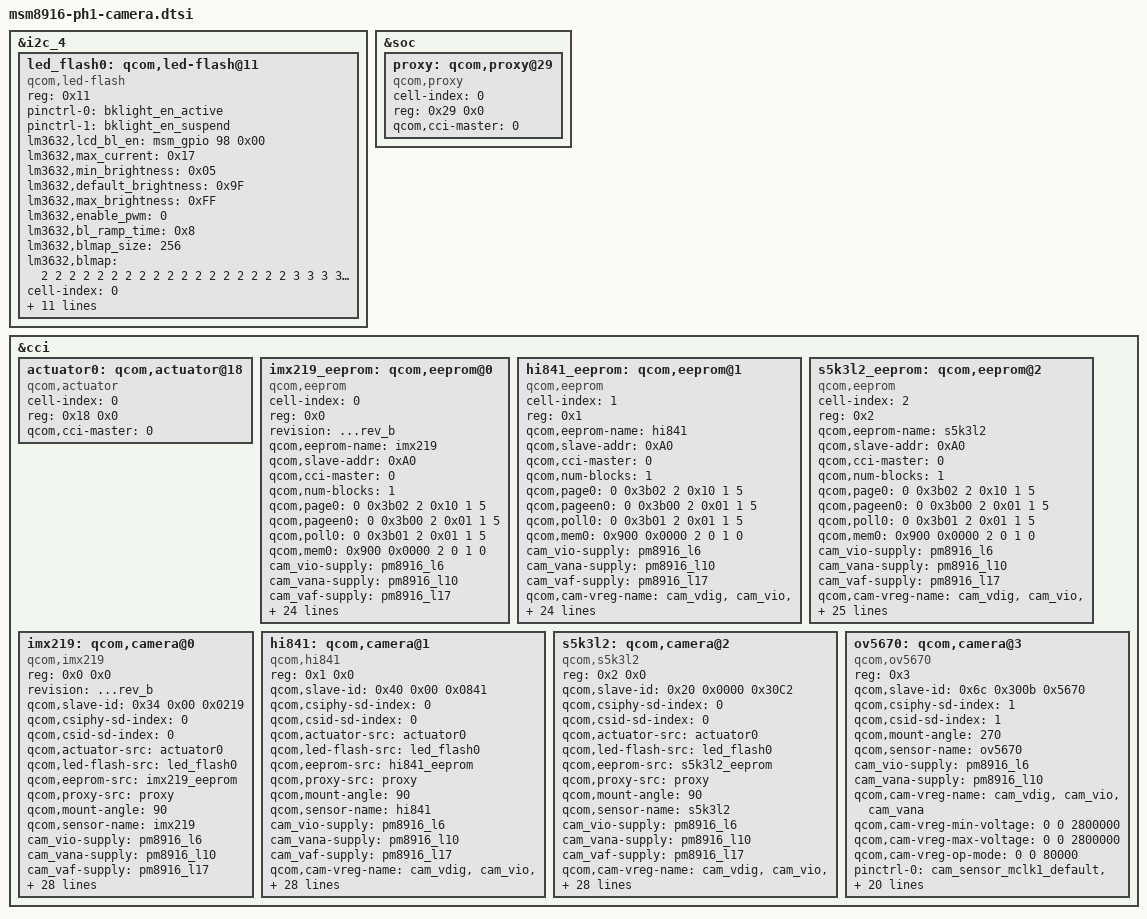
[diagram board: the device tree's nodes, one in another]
/*
 * Copyright (c) 2013, The Linux Foundation. All rights reserved.
 *
 * This program is free software; you can redistribute it and/or modify
 * it under the terms of the GNU General Public License version 2 and
 * only version 2 as published by the Free Software Foundation.
 *
 * This program is distributed in the hope that it will be useful,
 * but WITHOUT ANY WARRANTY; without even the implied warranty of
 * MERCHANTABILITY or FITNESS FOR A PARTICULAR PURPOSE.  See the
 * GNU General Public License for more details.
 */

&i2c_4 {
	led_flash0: qcom,led-flash@11 {
		compatible                = "qcom,led-flash";
		status                    = "ok";
		reg                       = <0x11>;

		pinctrl-names = "default", "sleep";
		pinctrl-0 = <&bklight_en_active>;
		pinctrl-1 = <&bklight_en_suspend>;

		lm3632,lcd_bl_en = <&msm_gpio 98 0x00>;
		lm3632,max_current = <0x17>;
		lm3632,min_brightness = <0x05>;
		lm3632,default_brightness = <0x9F>;
		lm3632,max_brightness = <0xFF>;
		lm3632,enable_pwm = <0>;
		lm3632,bl_ramp_time = <0x8>; // 50msec
		lm3632,blmap_size = <256>;
		lm3632,blmap = <
			/*   0 */    2   2   2   2   2   2   2   2   2   2
			/*  10 */    2   2   2   2   2   2   2   2   3   3
			/*  20 */    3   3   3   3   3   3   4   4   4   4
			/*  30 */    4   4   4   4   5   5   5   5   5   5
			/*  40 */    5   5   5   6   6   6   6   6   6   6
			/*  50 */    6   6   7   7   7   7   7   7   7   7
			/*  60 */    8   8   9   9   9   9  10  10  11  11
			/*  70 */   11  12  12  13  13  13  14  14  15  15
			/*  80 */   15  16  16  17  17  17  18  18  18  19
			/*  90 */   19  19  20  20  20  21  21  21  22  22
			/* 100 */   22  23  23  24  24  24  25  25  25  26
			/* 110 */   26  27  28  28  29  29  30  31  31  32
			/* 120 */   33  34  34  35  36  37  37  38  39  40
			/* 130 */   40  41  42  43  43  44  45  46  46  47
			/* 140 */   47  48  48  49  50  51  51  52  53  54
			/* 150 */   54  55  55  56  56  57  58  59  59  60
			/* 160 */   61  62  63  64  65  66  67  69  70  71
			/* 170 */   72  73  74  76  77  78  79  80  81  82
			/* 180 */   83  84  85  86  88  89  91  92  93  94
			/* 190 */   95  96  97  98  99 100 101 102 103 104
			/* 200 */  105 106 107 108 109 110 111 112 114 115
			/* 210 */  117 119 121 123 124 125 127 128 129 131
			/* 220 */  133 134 136 138 139 141 143 144 145 146
			/* 230 */  148 150 151 153 154 155 157 158 159 161
			/* 240 */  163 165 167 169 171 172 174 175 177 178
			/* 250 */  179 181 183 184 186 187 >;

		cell-index = <0>;
		label                   = "lm3632";
		qcom,flash-name         = "lm3632";
		qcom,slave-id           = <0x11 0x01 0x01>;
		qcom,flash-type         = <1>;              // LED_FLASH
		qcom,gpio-no-mux        = <0>;
		gpios                   = <&msm_gpio 31 0>; // FLASH_STROBE_TRIG, GPIO 31
		qcom,gpio-flash-en      = <0>;
		qcom,gpio-req-tbl-num   = <0>;
		qcom,gpio-req-tbl-flags = <0>;
		qcom,gpio-req-tbl-label = "FLASH_EN";
		qcom,cci-master = <0>;
	};
};

&soc {
    proxy: qcom,proxy@29 {
        cell-index = <0>;
        reg = <0x29 0x0>;
        compatible = "qcom,proxy";
        qcom,cci-master = <0>;
    };
};

&cci {
	actuator0: qcom,actuator@18 {
		cell-index = <0>;
		reg = <0x18 0x0>;
		compatible = "qcom,actuator";
		qcom,cci-master = <0>;
	};

	imx219_eeprom: qcom,eeprom@0 {
		status = "ok";
		cell-index = <0>;
		reg = <0x0>;
		revision = "...rev_b";
		qcom,eeprom-name = "imx219";
		compatible = "qcom,eeprom";
		qcom,slave-addr = <0xA0>;
		qcom,cci-master = <0>;
		qcom,num-blocks = <1>;

		qcom,page0 = <0 0x3b02 2 0x10 1 5>;
		qcom,pageen0 = <0 0x3b00 2 0x01 1 5>;
		qcom,poll0 = <0 0x3b01 2 0x01 1 5>;
		qcom,mem0 = <0x900 0x0000 2 0 1 0>;

		cam_vio-supply = <&pm8916_l6>;   //1V8_VREG_L6 (always-on)
		cam_vana-supply = <&pm8916_l10>; //2V8_VREG_L10
		cam_vaf-supply = <&pm8916_l17>;  //2V85_VREG_L17
		qcom,cam-vreg-name = "cam_vdig", "cam_vio", "cam_vana", "cam_vaf";
		qcom,cam-vreg-min-voltage = <0 0 2800000 2850000>;
		qcom,cam-vreg-max-voltage = <0 0 2800000 2850000>;
		qcom,cam-vreg-op-mode = <0 0 80000 100000>;

		pinctrl-names = "cam_default", "cam_suspend";
		pinctrl-0 = <&cam_sensor_mclk0_default &cam_sensor_rear_default>;
		pinctrl-1 = <&cam_sensor_mclk0_sleep &cam_sensor_rear_sleep>;

		gpios = <&msm_gpio 26 0>,
			    <&msm_gpio 35 0>,
			    <&msm_gpio 121 0>;

		qcom,gpio-no-mux = <0>;
		qcom,gpio-reset  = <1>;
		qcom,gpio-vdig   = <2>;
		qcom,gpio-req-tbl-num   = <0 1 2>;
		qcom,gpio-req-tbl-flags = <1 0 0>;
		qcom,gpio-req-tbl-label = "CAMIF_MCLK", "CAM_RESET1", "CAM_DVDD";
		qcom,csi-lane-assign = <0x4320>;
		qcom,csi-lane-mask   = <0x1F>;

		qcom,cam-power-seq-type = "sensor_vreg";
		qcom,cam-power-seq-val = "cam_vio";
		qcom,cam-power-seq-cfg-val = <1>;
		qcom,cam-power-seq-delay = <20>;
		qcom,mclk-23880000;
	};

	hi841_eeprom: qcom,eeprom@1 {
		status = "ok";
		cell-index = <1>;
		reg = <0x1>;
		qcom,eeprom-name = "hi841";
		compatible = "qcom,eeprom";
		qcom,slave-addr = <0xA0>;
		qcom,cci-master = <0>;
		qcom,num-blocks = <1>;

		qcom,page0 = <0 0x3b02 2 0x10 1 5>;
		qcom,pageen0 = <0 0x3b00 2 0x01 1 5>;
		qcom,poll0 = <0 0x3b01 2 0x01 1 5>;
		qcom,mem0 = <0x900 0x0000 2 0 1 0>;

		cam_vio-supply = <&pm8916_l6>;
		cam_vana-supply = <&pm8916_l10>;
		cam_vaf-supply = <&pm8916_l17>;
		qcom,cam-vreg-name = "cam_vdig", "cam_vio", "cam_vana", "cam_vaf";
		qcom,cam-vreg-min-voltage = <0 0 2800000 2850000>;
		qcom,cam-vreg-max-voltage = <0 0 2800000 2850000>;
		qcom,cam-vreg-op-mode = <0 0 80000 100000>;

		pinctrl-names = "cam_default", "cam_suspend";
		pinctrl-0 = <&cam_sensor_mclk0_default &cam_sensor_rear_default>;
		pinctrl-1 = <&cam_sensor_mclk0_sleep &cam_sensor_rear_sleep>;

		gpios = <&msm_gpio 26 0>,
			    <&msm_gpio 35 0>,
			    <&msm_gpio 121 0>;

		qcom,gpio-no-mux = <0>;
		qcom,gpio-reset  = <1>;
		qcom,gpio-vdig   = <2>;
		qcom,gpio-req-tbl-num   = <0 1 2>;
		qcom,gpio-req-tbl-flags = <1 0 0>;
		qcom,gpio-req-tbl-label = "CAMIF_MCLK", "CAM_RESET1", "CAM_DVDD";
		qcom,csi-lane-assign = <0x4320>;
		qcom,csi-lane-mask   = <0x1F>;

		qcom,cam-power-seq-type = "sensor_vreg";
		qcom,cam-power-seq-val = "cam_vio";
		qcom,cam-power-seq-cfg-val = <1>;
		qcom,cam-power-seq-delay = <20>;
		qcom,mclk-23880000;

		lge,eeprom-position = <0>;
	};

	s5k3l2_eeprom: qcom,eeprom@2 {
		status = "ok";
		cell-index = <2>;
		reg = <0x2>;
		qcom,eeprom-name = "s5k3l2";
		compatible = "qcom,eeprom";
		qcom,slave-addr = <0xA0>;
		qcom,cci-master = <0>;
		qcom,num-blocks = <1>;

		qcom,page0 = <0 0x3b02 2 0x10 1 5>;
		qcom,pageen0 = <0 0x3b00 2 0x01 1 5>;
		qcom,poll0 = <0 0x3b01 2 0x01 1 5>;
		qcom,mem0 = <0x900 0x0000 2 0 1 0>;

		cam_vio-supply = <&pm8916_l6>;
		cam_vana-supply = <&pm8916_l10>;
		cam_vaf-supply = <&pm8916_l17>;

		qcom,cam-vreg-name = "cam_vdig", "cam_vio", "cam_vana", "cam_vaf";
		qcom,cam-vreg-min-voltage = <0 0 2800000 2850000>;
		qcom,cam-vreg-max-voltage = <0 0 2800000 2850000>;
		qcom,cam-vreg-op-mode = <0 0 80000 100000>;

		pinctrl-names = "cam_default", "cam_suspend";
		pinctrl-0 = <&cam_sensor_mclk0_default &cam_sensor_rear_default>;
		pinctrl-1 = <&cam_sensor_mclk0_sleep &cam_sensor_rear_sleep>;

		gpios = <&msm_gpio 26 0>,
		        <&msm_gpio 35 0>,
		        <&msm_gpio 121 0>,
				<&msm_gpio 109 0>;

		qcom,gpio-no-mux	= <0>;
		qcom,gpio-reset		= <1>;
		qcom,gpio-vdig		= <2>;
		qcom,gpio-ldaf-en	= <3>;
		qcom,gpio-req-tbl-num	= <0 1 2 3>;
		qcom,gpio-req-tbl-flags	= <1 0 0 0>;
		qcom,gpio-req-tbl-label	= "CAMIF_MCLK",
		                          "CAM_RESET1",
		                          "CAM_DVDD",
					  "LDAF_EN";

		qcom,csi-lane-assign = <0x4320>;
		qcom,csi-lane-mask   = <0x1F>;

		qcom,cam-power-seq-type = "sensor_vreg";
		qcom,cam-power-seq-val = "cam_vio";
		qcom,cam-power-seq-cfg-val = <1>;
		qcom,cam-power-seq-delay = <20>;
		qcom,mclk-23880000;
	};

	imx219: qcom,camera@0 {
		status = "ok";
		compatible = "qcom,imx219";
		reg = <0x0 0x0>;
		revision = "...rev_b";
		qcom,slave-id = <0x34 0x00 0x0219>;
		qcom,csiphy-sd-index = <0>;
		qcom,csid-sd-index = <0>;
		qcom,actuator-src = <&actuator0>;
		qcom,led-flash-src = <&led_flash0>;
		qcom,eeprom-src = <&imx219_eeprom>;
		qcom,proxy-src       = <&proxy>;
		qcom,mount-angle = <90>;
		qcom,sensor-name = "imx219";

		cam_vio-supply = <&pm8916_l6>;		// always-on
		cam_vana-supply = <&pm8916_l10>;
		cam_vaf-supply = <&pm8916_l17>;
		qcom,cam-vreg-name = "cam_vdig", "cam_vio", "cam_vana", "cam_vaf";
		qcom,cam-vreg-min-voltage = <0 0 2800000 2850000>;
		qcom,cam-vreg-max-voltage = <0 0 2800000 2850000>;
		qcom,cam-vreg-op-mode = <0 0 80000 100000>;

		pinctrl-names = "cam_default", "cam_suspend";
		pinctrl-0 = <&cam_sensor_mclk0_default &cam_sensor_rear_default>;
		pinctrl-1 = <&cam_sensor_mclk0_sleep &cam_sensor_rear_sleep>;

		gpios = <&msm_gpio 26 0>,
				<&msm_gpio 35 0>,
				<&msm_gpio 121 0>,
				<&msm_gpio 109 0>;

		qcom,gpio-no-mux = <0>;
		qcom,gpio-reset  = <1>;
		qcom,gpio-vdig   = <2>;     // CAM_DVDD_1V2
		qcom,gpio-ldaf-en = <3>;
		qcom,gpio-req-tbl-num   = <0 1 2 3>;
		qcom,gpio-req-tbl-flags = <1 0 0 0>;
		qcom,gpio-req-tbl-label = "CAMIF_MCLK", "CAM_RESET1", "CAM_DVDD", "LDAF_EN";
		qcom,csi-lane-assign = <0x4320>;
		qcom,csi-lane-mask   = <0x1F>;
		qcom,sensor-position = <0>;
		qcom,sensor-mode     = <0>;
		qcom,cci-master      = <0>;

		clocks = <&clock_gcc clk_mclk0_clk_src>,
				 <&clock_gcc clk_gcc_camss_mclk0_clk>;
		clock-names = "cam_src_clk", "cam_clk";
		qcom,mclk-23880000;
		lge,vcm-pwdn = "dw9718";
	};

	hi841: qcom,camera@1 {
		status = "ok";
		compatible = "qcom,hi841";
		reg = <0x1 0x0>;
		qcom,slave-id = <0x40 0x00 0x0841>;
		qcom,csiphy-sd-index = <0>;
		qcom,csid-sd-index = <0>;
		qcom,actuator-src = <&actuator0>;
		qcom,led-flash-src = <&led_flash0>;
		qcom,eeprom-src = <&hi841_eeprom>;
		qcom,proxy-src       = <&proxy>;
		qcom,mount-angle = <90>;
		qcom,sensor-name = "hi841";

		cam_vio-supply = <&pm8916_l6>;		//always-on
		cam_vana-supply = <&pm8916_l10>;
		cam_vaf-supply = <&pm8916_l17>;
		qcom,cam-vreg-name = "cam_vdig", "cam_vio", "cam_vana", "cam_vaf";
		qcom,cam-vreg-min-voltage = <0 0 2800000 2850000>;
		qcom,cam-vreg-max-voltage = <0 0 2800000 2850000>;
		qcom,cam-vreg-op-mode = <0 0 80000 100000>;

		pinctrl-names = "cam_default", "cam_suspend";
		pinctrl-0 = <&cam_sensor_mclk0_default &cam_sensor_rear_default &cam_ldaf_enable_default>;
		pinctrl-1 = <&cam_sensor_mclk0_sleep &cam_sensor_rear_sleep &cam_ldaf_enable_sleep>;

		gpios = <&msm_gpio 26 0>,
				<&msm_gpio 35 0>,
				<&msm_gpio 121 0>,
				<&msm_gpio 109 0>;

		qcom,gpio-no-mux = <0>;
		qcom,gpio-reset  = <1>;
		qcom,gpio-vdig   = <2>;
		qcom,gpio-ldaf-en = <3>;
		qcom,gpio-req-tbl-num   = <0 1 2 3>;
		qcom,gpio-req-tbl-flags = <1 0 0 0>;
		qcom,gpio-req-tbl-label = "CAMIF_MCLK", "CAM_RESET1", "CAM_DVDD", "LDAF_EN";
		qcom,csi-lane-assign = <0x4320>;
		qcom,csi-lane-mask   = <0x1F>;
		qcom,sensor-position = <0>;
		qcom,sensor-mode     = <0>;
		qcom,cci-master      = <0>;

		clocks = <&clock_gcc clk_mclk0_clk_src>,
				 <&clock_gcc clk_gcc_camss_mclk0_clk>;
		clock-names = "cam_src_clk", "cam_clk";
		qcom,mclk-23880000;
		lge,vcm-pwdn = "dw9718";
	};

	s5k3l2: qcom,camera@2 {
		compatible           = "qcom,s5k3l2";
		reg                  = <0x2 0x0>;
		qcom,slave-id        = <0x20 0x0000 0x30C2>;
		qcom,csiphy-sd-index = <0>;
		qcom,csid-sd-index   = <0>;
		qcom,actuator-src    = <&actuator0>;
		qcom,led-flash-src   = <&led_flash0>;
		qcom,eeprom-src      = <&s5k3l2_eeprom>;
		qcom,proxy-src       = <&proxy>;
		qcom,mount-angle     = <90>;
		qcom,sensor-name     = "s5k3l2";

		cam_vio-supply = <&pm8916_l6>;   //1V8_VREG_L6 (always-on)
		cam_vana-supply = <&pm8916_l10>; //2V8_VREG_L10
		cam_vaf-supply = <&pm8916_l17>;  //2V85_VREG_L17

		qcom,cam-vreg-name = "cam_vdig", "cam_vio", "cam_vana", "cam_vaf";
		qcom,cam-vreg-min-voltage = <0 0 2800000 2850000>;
		qcom,cam-vreg-max-voltage = <0 0 2800000 2850000>;
		qcom,cam-vreg-op-mode = <0 0 80000 100000>;

		pinctrl-names = "cam_default", "cam_suspend";
		pinctrl-0 = <&cam_sensor_mclk0_default &cam_sensor_rear_default &cam_ldaf_enable_default>;
		pinctrl-1 = <&cam_sensor_mclk0_sleep &cam_sensor_rear_sleep &cam_ldaf_enable_sleep>;

		gpios = <&msm_gpio 26 0>,	//MAIN_CAM0_MCLK
		        <&msm_gpio 35 0>,	//MAIN_CAM0_RESET_N --> StandBY
		        <&msm_gpio 121 0>,	//CAM_DVDD_1.2V,  LDO2_EN=GPIO 120 //Why 1V05 ????
			<&msm_gpio 109 0>;	//LDAF_EN

		qcom,gpio-no-mux    = <0>;
		qcom,gpio-reset  = <1>;
		qcom,gpio-vdig      = <2>;
		qcom,gpio-ldaf-en	= <3>;
		qcom,gpio-req-tbl-num	= <0 1 2 3>;
		qcom,gpio-req-tbl-flags	= <1 0 0 0>;
		qcom,gpio-req-tbl-label	= "CAMIF_MCLK",
		                          "CAM_RESET1",
		                          "CAM_DVDD",
					  "LDAF_EN";

		qcom,csi-lane-assign = <0x4320>;
		qcom,csi-lane-mask   = <0x1F>;
		qcom,sensor-position = <0>;
		qcom,sensor-mode     = <0>;
		qcom,cci-master      = <0>;

		status = "ok";
		clocks = <&clock_gcc clk_mclk0_clk_src>,
				 <&clock_gcc clk_gcc_camss_mclk0_clk>;
		clock-names = "cam_src_clk", "cam_clk";
		qcom,mclk-23880000;
		lge,vcm-pwdn = "dw9718";
	};

	ov5670: qcom,camera@3 {
		status = "ok";
		compatible           = "qcom,ov5670";
		reg                  = <0x3>;
		qcom,slave-id        = <0x6c 0x300b 0x5670>;
		qcom,csiphy-sd-index = <1>;
		qcom,csid-sd-index   = <1>;
		qcom,mount-angle     = <270>;
		qcom,sensor-name     = "ov5670";

		cam_vio-supply  = <&pm8916_l6>;		//always-on
		cam_vana-supply = <&pm8916_l10>;
		qcom,cam-vreg-name = "cam_vdig", "cam_vio", "cam_vana";
		qcom,cam-vreg-min-voltage = <0 0 2800000>;
		qcom,cam-vreg-max-voltage = <0 0 2800000>;
		qcom,cam-vreg-op-mode     = <0 0   80000>;

		pinctrl-names = "cam_default", "cam_suspend";
		pinctrl-0 = <&cam_sensor_mclk1_default &cam_sensor_front_default>;
		pinctrl-1 = <&cam_sensor_mclk1_sleep &cam_sensor_front_sleep>;

		gpios = <&msm_gpio 27  0>,
		        <&msm_gpio 28  0>,
				<&msm_gpio 121 0>;

		qcom,gpio-no-mux  = <0>;
		qcom,gpio-reset   = <1>;
		qcom,gpio-vdig    = <2>;

		qcom,gpio-req-tbl-num   = <0 1 2>;
		qcom,gpio-req-tbl-flags = <1 0 0>;
		qcom,gpio-req-tbl-label = "CAMIF_MCLK2",
		                          "CAM_RESET2",
		                          "MAIN_VDIG_EN2";

		qcom,csi-lane-assign    = <0x4320>;
		qcom,csi-lane-mask      = <0x7>;
		qcom,sensor-position    = <1>;
		qcom,sensor-mode        = <1>;
		qcom,cci-master         = <0>;

		clocks = <&clock_gcc clk_mclk1_clk_src>,
		         <&clock_gcc clk_gcc_camss_mclk1_clk>;
		clock-names = "cam_src_clk", "cam_clk";

		qcom,gpio-maker-id = <&msm_gpio 11 0x0>;
		qcom,mclk-23880000;
	};
};
